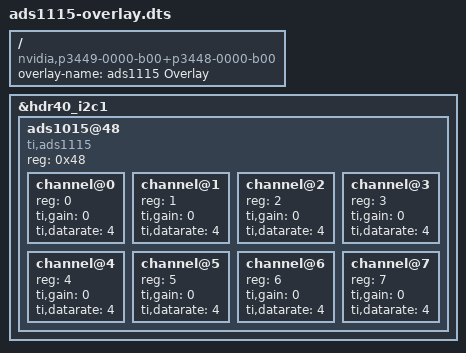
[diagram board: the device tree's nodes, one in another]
/dts-v1/;
/plugin/;
 
/ {
    overlay-name = "ads1115 Overlay";
    compatible = "nvidia,p3449-0000-b00+p3448-0000-b00";
 
    fragment@0 {
        target = <&hdr40_i2c1>;
        __overlay__ {
             ads1015@48 {
        	    compatible = "ti,ads1115";
        	    reg = <0x48>;
        	    #address-cells = <1>;
        	    #size-cells = <0>;
                
                channel@0 {
            	    reg = <0>;
            	    ti,gain = <0>;
            	    ti,datarate = <4>;
                };
                
                channel@1 {
            	    reg = <1>;
            	    ti,gain = <0>;
            	    ti,datarate = <4>;
                };
                
                channel@2 {
            	    reg = <2>;
            	    ti,gain = <0>;
            	    ti,datarate = <4>;
                };
                
                
                channel@3 {
            	    reg = <3>;
            	    ti,gain = <0>;
            	    ti,datarate = <4>;
                };
                
                channel@4 {
            	    reg = <4>;
            	    ti,gain = <0>;
            	    ti,datarate = <4>;
                };
                
                channel@5 {
            	    reg = <5>;
            	    ti,gain = <0>;
            	    ti,datarate = <4>;
                };
                
                
                channel@6 {
            	    reg = <6>;
            	    ti,gain = <0>;
            	    ti,datarate = <4>;
                };
                
                channel@7 {
            	    reg = <7>;
            	    ti,gain = <0>;
            	    ti,datarate = <4>;
                };
            };
        };
    };
};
